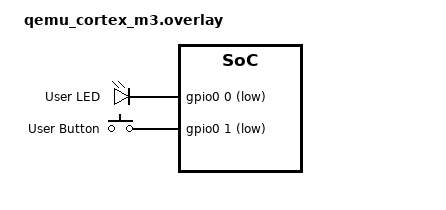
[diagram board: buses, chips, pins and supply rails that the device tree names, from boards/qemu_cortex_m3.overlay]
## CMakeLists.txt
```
# SPDX-License-Identifier: Apache-2.0

cmake_minimum_required(VERSION 3.20.0)

find_package(Zephyr REQUIRED HINTS $ENV{ZEPHYR_BASE})
project(atv2_se)

target_sources(app PRIVATE src/main.c)
```

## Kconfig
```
# SPDX-License-Identifier: Apache-2.0

mainmenu "Configurações do Hello Timer"

# Importa as opções padrão do Zephyr (logs, console, UART etc.)
rsource "$ZEPHYR_BASE/Kconfig.zephyr"

menu "Configurações do Hello Timer"

config HELLO_INTERVAL
    int "Intervalo do Hello (ms)"
    default 1000
    help
      Define o intervalo em milissegundos entre as mensagens do timer.

endmenu
```

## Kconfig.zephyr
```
menu "Configurações do Hello World Timer"

config HELLO_INTERVAL
    int "Intervalo do timer em milissegundos"
    default 1000
    help
      Define o intervalo em que a mensagem Hello World será exibida.

endmenu
```

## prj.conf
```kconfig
# Console
CONFIG_PRINTK=y
CONFIG_STDOUT_CONSOLE=y

# Para sys_rand32_get()
CONFIG_TEST_RANDOM_GENERATOR=y

# Logs (opcional)
CONFIG_LOG=y
CONFIG_LOG_DEFAULT_LEVEL=3

# Aumentar a stack da main (dependendo da placa)
CONFIG_MAIN_STACK_SIZE=1024
```

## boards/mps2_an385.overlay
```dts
/ {
    leds {
        compatible = "gpio-leds";

        led0: led_0 {
            gpios = <&gpio0 0 0>;
            label = "GNSS LED";
        };

        led1: led_1 {
            gpios = <&gpio0 1 0>;
            label = "LTE LED";
        };
    };

    aliases {
        led0 = &led0;
        led1 = &led1;
    };
};
```

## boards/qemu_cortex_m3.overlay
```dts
/ {
    aliases {
        led0 = &led0;
        sw0 = &button0;
        pwm_led0 = &pwm0;
    };

    leds {
        compatible = "gpio-leds";
        led0: led0 {
            gpios = <&gpio0 0 GPIO_ACTIVE_LOW>;
            label = "User LED";
        };
    };

    buttons {
        compatible = "gpio-keys";
        button0: button_0 {
            gpios = <&gpio0 1 GPIO_ACTIVE_LOW>;
            label = "User Button";
        };
    };

    pwm0: pwm0 {
        compatible = "pwm-leds";
        pwms = <&gpio0 0 0>;
    };
};
```

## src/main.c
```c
#include <zephyr/kernel.h>
#include <zephyr/sys/printk.h>
#include <zephyr/random/random.h>
#include <string.h>

typedef struct {
    char tipo;      // 'T' = temperatura, 'U' = umidade
    int valor;
} sensor_msg_t;

typedef struct {
    char texto[64];
} log_msg_t;

K_MSGQ_DEFINE(msgq_in,  sizeof(sensor_msg_t), 10, 4);
K_MSGQ_DEFINE(msgq_out, sizeof(sensor_msg_t), 10, 4);
K_MSGQ_DEFINE(logq,     sizeof(log_msg_t),    10, 4);



void enviar_para_log(const char *msg)
{
    log_msg_t lm;
    strncpy(lm.texto, msg, sizeof(lm.texto) - 1);
    lm.texto[sizeof(lm.texto) - 1] = '\0';

    k_msgq_put(&logq, &lm, K_NO_WAIT);
}


void produtor_temp(void)
{
    while (1) {
        sensor_msg_t msg = {
            .tipo = 'T',
            .valor = 18 + (sys_rand32_get() % 20)  // entre 18 e 37
        };

        k_msgq_put(&msgq_in, &msg, K_FOREVER);
        printk("[TEMP] Produzido: %d C\n", msg.valor);
        k_sleep(K_MSEC(1500));
    }
}

void produtor_umid(void)
{
    while (1) {
        sensor_msg_t msg = {
            .tipo = 'U',
            .valor = 30 + (sys_rand32_get() % 50)  // entre 30 e 79
        };

        k_msgq_put(&msgq_in, &msg, K_FOREVER);
        printk("[UMID] Produzido: %d %%\n", msg.valor);
        k_sleep(K_MSEC(1700));
    }
}

void filtro(void)
{
    sensor_msg_t entrada;

    while (1) {
        k_msgq_get(&msgq_in, &entrada, K_FOREVER);

        bool valido = false;

        if (entrada.tipo == 'T') {
            valido = (entrada.valor >= 18 && entrada.valor <= 30);
        } else if (entrada.tipo == 'U') {
            valido = (entrada.valor >= 40 && entrada.valor <= 70);
        }

        if (valido) {
            k_msgq_put(&msgq_out, &entrada, K_FOREVER);
        } else {
            char log_msg[64];
            snprintf(log_msg, sizeof(log_msg),
                     "Dado invalido (%c=%d)", entrada.tipo, entrada.valor);
            enviar_para_log(log_msg);
        }
    }
}

void consumidor(void)
{
    sensor_msg_t msg;

    while (1) {
        k_msgq_get(&msgq_out, &msg, K_FOREVER);

        if (msg.tipo == 'T') {
            printk("[CONS] Temperatura: %d C\n", msg.valor);
        } else {
            printk("[CONS] Umidade: %d %%\n", msg.valor);
        }
    }
}

void thread_log(void)
{
    log_msg_t lm;

    while (1) {
        k_msgq_get(&logq, &lm, K_FOREVER);
        printk("[LOG] %s\n", lm.texto);
    }
}

K_THREAD_DEFINE(th_temp,   1024, produtor_temp,  NULL, NULL, NULL, 3, 0, 0);
K_THREAD_DEFINE(th_umid,   1024, produtor_umid,  NULL, NULL, NULL, 3, 0, 0);
K_THREAD_DEFINE(th_filtro, 1024, filtro,         NULL, NULL, NULL, 2, 0, 0);
K_THREAD_DEFINE(th_cons,   1024, consumidor,     NULL, NULL, NULL, 1, 0, 0);
K_THREAD_DEFINE(th_log,    1024, thread_log,     NULL, NULL, NULL, 4, 0, 0);
```
